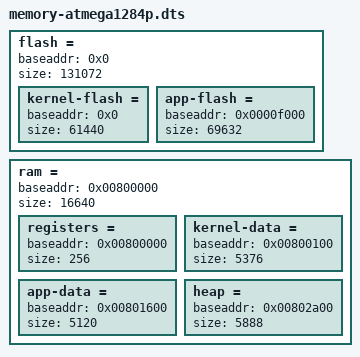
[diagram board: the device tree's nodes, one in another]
/**
 * Copyright (C) 2022 Jan Nowotsch
 * Author Jan Nowotsch	<jan.nowotsch@gmail.com>
 *
 * Released under the terms of the GNU GPL v2.0
 */



flash = {
	baseaddr = 0x0;
	size = 131072;

	kernel-flash = {
		baseaddr = 0x0;
		size = 61440;
	};

	app-flash = {
		baseaddr = 0x0000f000;
		size = 69632;
	};
};

ram = {
	baseaddr = 0x00800000;
	size = 16640;

	registers = {
		baseaddr = 0x00800000;
		size = 256;
	};

	kernel-data = {
		baseaddr = 0x00800100;
		size = 5376;
	};

	app-data = {
		baseaddr = 0x00801600;
		size = 5120;
	};

	heap = {
		baseaddr = 0x00802a00;
		size = 5888;
	};
};
